# SAM9X70 register map
Vendor: Microchip Technology; Series: SAM9X7; File version: 0
Registers are 32-bit, read-write, reset 0x0 unless marked. A register's access mark holds for its fields unless they carry their own. Offsets are from the block's base; [hi:lo] are bit positions; lines under a group give offsets from that group; {n}, {i} and the like mark numbered series; 'fields as' and 'values as' point back to an identical list.

## BSC — Boot Sequence Controller
Base 0xFFFFFE54
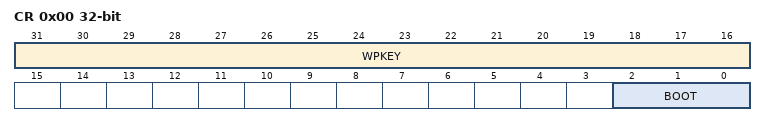
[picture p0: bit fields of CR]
0x00 CR — Boot Sequence Controller Configuration Register
  [31:16] WPKEY — Write Protection Key (Write-only)
    0x6683=PASSWD (Writing any other value in this field aborts the write operation of the BOOT field. Always reads as 0.)
  [2:0] BOOT — Boot Media Sequence

## GPBR — General Purpose Backup Registers
Base 0xFFFFFE60
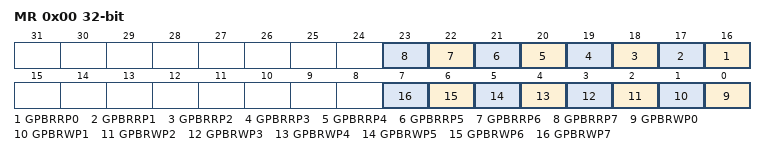
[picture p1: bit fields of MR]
0x00 MR — GPBR Mode Register
  [n+16] GPBRRP{n} (n=0..7) — GPBRx Read Protection
    0=The content of the corresponding GPBR register (32-bit part-select) can be read; 1=The corresponding GPBR register (32-bit part-select) always returns zero when read
  [n] GPBRWP{n} (n=0..7) — GPBRx Write Protection
    0=The corresponding GPBR register (32-bit part-select) can be written; 1=The corresponding GPBR register (32-bit part-select) is write-protected
0x04 FCLR — GPBR Full Clear Register
  [0] FCLR — Full Clear Enable
    0=SYS_GPBR0 to SYS_GPBR3 are immediately cleared in case of fast wake-up pin tamper event; 1=All SYS_GPBRx are immediately cleared in case of fast wake-up pin tamper event
{0x8+4i} SYS_GPBR[{i}] (i=0..7) — General Purpose Backup Register x
  [31:0] GPBR_VALUE — Value of SYS_GPBRx

## PIT — Periodic Interval Timer
Base 0xFFFFFE40
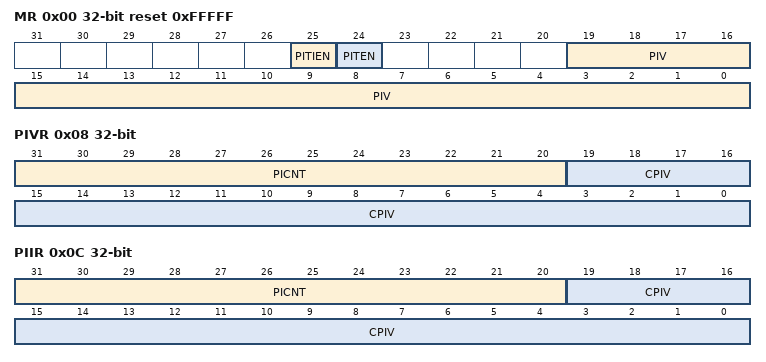
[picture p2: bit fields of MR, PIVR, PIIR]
0x00 MR reset 0xFFFFF — Mode Register
  [25] PITIEN — Periodic Interval Timer Interrupt Enable
    0=The bit PITS in PIT_SR has no effect on interrupt; 1=The bit PITS in PIT_SR asserts interrupt
  [24] PITEN — Period Interval Timer Enabled
    0=The Periodic Interval Timer is disabled when the PIV value is reached; 1=The Periodic Interval Timer is enabled
  [19:0] PIV — Periodic Interval Value
0x04 SR ro — Status Register
  [0] PITS — Periodic Interval Timer Status
    0=The Periodic Interval timer has not reached PIV since the last read of PIT_PIVR; 1=The Periodic Interval timer has reached PIV since the last read of PIT_PIVR
0x08 PIVR ro — Periodic Interval Value Register
  [31:20] PICNT — Periodic Interval Counter
  [19:0] CPIV — Current Periodic Interval Value
0x0C PIIR ro — Periodic Interval Image Register
  fields as PIVR

## PMECC — IP_Name
Base 0xFFFFE000
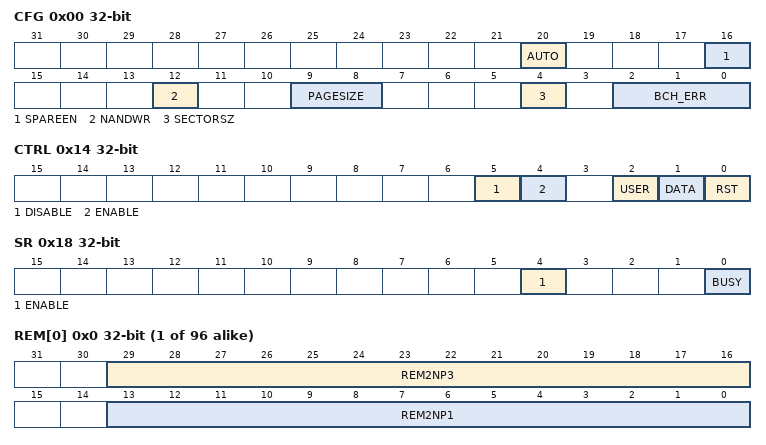
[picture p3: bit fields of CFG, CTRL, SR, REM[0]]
0x00 CFG — PMECC Configuration Register
  [20] AUTO — Automatic Mode Enable
    0=Indicates that the spare area is not protected. In that case the ECC computation takes into account the ECC area located in the spare area. (within the start address and the end address).; 1=Indicates that the spare is error protected. In this case, the ECC computation takes into account the whole spare area minus the ECC area in the ECC computation operation.
  [16] SPAREEN — Spare Enable
    0=The spare area is skipped; 1=The spare area is protected with the last sector of data
  [12] NANDWR — NAND Write Access
    0=NAND read access; 1=NAND write access
  [9:8] PAGESIZE — Number of Sectors in the Page
    0=PAGESIZE_1SEC (1 sector for main area (512 or 1024 bytes)); 1=PAGESIZE_2SEC (2 sectors for main area (1024 or 2048 bytes)); 2=PAGESIZE_4SEC (4 sectors for main area (2048 or 4096 bytes)); 3=PAGESIZE_8SEC (8 errors for main area (4096 or 8192 bytes))
  [4] SECTORSZ — Sector Size
    0=The ECC computation is based on a sector of 512 bytes; 1=The ECC computation is based on a sector of 1024 bytes
  [2:0] BCH_ERR — Error Correct Capability
    0=2 errors; 1=4 errors; 2=8 errors; 3=12 errors; 4=24 errors
0x04 SAREA — PMECC Spare Area Size Register
  [8:0] SPARESIZE — Spare Area Size
0x08 SADDR — PMECC Start Address Register
  [8:0] STARTADDR — ECC Area Start Address (byte oriented address)
0x0C EADDR — PMECC End Address Register
  [8:0] ENDADDR — ECC Area End Address (byte oriented address)
0x10 CLK — PMECC Clock Control Register
  [2:0] CLKCTRL — Clock Control Register
0x14 CTRL wo — PMECC Control Register
  [5] DISABLE — PMECC Module Disable
  [4] ENABLE — PMECC Module Enable
  [2] USER — Start a User Mode Phase
  [1] DATA — Start a Data Phase
  [0] RST — Reset the PMECC Module
0x18 SR ro — PMECC Status Register
  [4] ENABLE — PMECC Module Status
    0=The PMECC module is disabled and can be configured; 1=The PMECC module is enabled and the configuration registers cannot be written
  [0] BUSY — The Kernel of the PMECC is Busy
0x1C IER wo — PMECC Interrupt Enable register
  [0] ERRIE — Error Interrupt Enable
0x20 IDR wo — PMECC Interrupt Disable Register
  [0] ERRID — Error Interrupt Disable
0x24 IMR ro — PMECC Interrupt Mask Register
  [0] ERRIM — Error Interrupt Mask
0x28 ISR ro — PMECC Interrupt Status Register
  [7:0] ERRIS — Error Interrupt Status
{0x40+0x40*i} PMECC_ECC[{i}] (i=0..7) group
  {0x0+4j} ECC[{j}] (j=0..10) ro reset 0xFFFFFFFF — PMECC ECC x Register
    [31:0] ECC — BCH Redundancy
{0x240+0x40*i} PMECC_REM[{i}] (i=0..7) group
  {0x0+4j} REM[{j}] (j=0..11) ro — PMECC REM x Register
    [29:16] REM2NP3 — BCH Remainder 2 * N + 3
    [13:0] REM2NP1 — BCH Remainder 2 * N + 1

## Notices in the file
Copyright (c) 2026 Microchip Technology Inc.
SPDX-License-Identifier: Apache-2.0
Licensed under the Apache License, Version 2.0 (the "License");
you may not use this file except in compliance with the License.
You may obtain a copy of the License at
http://www.apache.org/licenses/LICENSE-2.0
Unless required by applicable law or agreed to in writing, software
distributed under the License is distributed on an "AS IS" BASIS,
WITHOUT WARRANTIES OR CONDITIONS OF ANY KIND, either express or implied.
See the License for the specific language governing permissions and
limitations under the License.
